# CY8C5888LTI_LP097 register map
File version: 0.1
CY8C58LP
Registers are 8-bit, read-write, no defined reset value unless marked. A register's access mark holds for its fields unless they carry their own. Offsets are from the block's base; lines under a group give offsets from that group; [hi:lo] are bit positions; {n}, {i} and the like mark numbered series; 'fields as' and 'values as' point back to an identical list; <NAME> marks a mode.

## Memory map
0x00000000 RC_Ch3_Timer
0x00000000 MPU6050_I2C
0x00000000 Flywheel_DC_Motor_PWM
0x00000000 Pendulum_DC_Motor_PWM
0x00000000 RC_Ch4_Timer
0x00000000 RC_Ch1_Timer
0x00000000 USBUART — USBFS
0x00000000 Drive_DC_Motor_PWM
0x00000000 RC_Ch2_Timer

## RC_Ch3_Timer
Base 0x00000000
0x40006404 RC_Ch3_Timer_COUNTER 24-bit — UDB.A0 - Current Down Counter Value
0x40006424 RC_Ch3_Timer_PERIOD 24-bit — UDB.D0 - Assigned Period
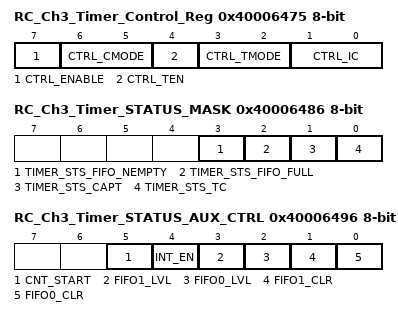
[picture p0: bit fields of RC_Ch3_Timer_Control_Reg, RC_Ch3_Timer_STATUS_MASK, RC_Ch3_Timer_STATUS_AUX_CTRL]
0x40006475 RC_Ch3_Timer_Control_Reg — UDB Control Register - Assigned Control Register Value
  [7] CTRL_ENABLE — Enable the Timer
  [6:5] CTRL_CMODE — Capture Mode
  [4] CTRL_TEN — Trigger Enable Bit
  [3:2] CTRL_TMODE — Trigger Mode
  [1:0] CTRL_IC — Interrupt Count
0x40006486 RC_Ch3_Timer_STATUS_MASK — UDB Status bits Interrupt Mask Enable Register
  [3] TIMER_STS_FIFO_NEMPTY ro — FIFO Empty status
  [2] TIMER_STS_FIFO_FULL ro — FIFO Full Status
  [1] TIMER_STS_CAPT ro — Enables the Interrupt on Capture
  [0] TIMER_STS_TC ro — Enables the Interrupt on TC
0x40006496 RC_Ch3_Timer_STATUS_AUX_CTRL — UDB Auxilliary Control Register
  [5] CNT_START — FIFO0 clear
    0=E_CNT_START0 (Disable counter); 1=E_CNT_START1 (Enable counter)
  [4] INT_EN
    0=E_INT_EN0 (Interrupt disabled); 1=E_INT_EN1 (Interrupt enabled)
  [3] FIFO1_LVL — FIFO level
    0=E_FIFO_LVL_0 (FIFO LVL: input mode: FIFO not full; output mode: FIFO not empty); 1=E_FIFO_LVL_1 (FIFO LVL: input mode: FIFO at least 1/2 empty; output mode: FIFO at least 1/2 full)
  [2] FIFO0_LVL — FIFO level
    values as FIFO1_LVL
  [1] FIFO1_CLR — FIFO1 clear
    0=E_FIFO_CLR_0 (Normal FIFO operation); 1=E_FIFO_CLR_1 (Clear FIFO state)
  [0] FIFO0_CLR — FIFO0 clear
    values as FIFO1_CLR

## Flywheel_DC_Motor_PWM
Base 0x00000000
0x40006427 Flywheel_DC_Motor_PWM__COMPARE1 — UDB.D0 - Assigned Compare1 Value
0x40006437 Flywheel_DC_Motor_PWM__COMPARE2 — UDB.D1 - Assigned Compare2 Value
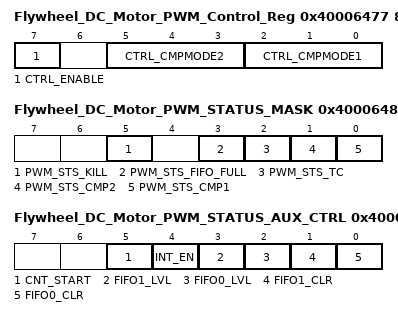
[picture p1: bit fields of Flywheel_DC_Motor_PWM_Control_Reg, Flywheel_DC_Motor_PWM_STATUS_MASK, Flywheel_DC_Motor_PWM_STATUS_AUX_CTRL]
0x40006477 Flywheel_DC_Motor_PWM_Control_Reg — UDB Control Register - Assigned Control Register Value
  [7] CTRL_ENABLE — Enable the PWM
  [5:3] CTRL_CMPMODE2 — Compare mode 2
  [2:0] CTRL_CMPMODE1 — Compare mode 1
0x40006487 Flywheel_DC_Motor_PWM_STATUS_MASK — UDB Status bits Interrupt Mask Enable Register
  [5] PWM_STS_KILL ro — Enables the Interrupt on Kill
  [3] PWM_STS_FIFO_FULL ro — FIFO Full Status Mask
  [2] PWM_STS_TC ro — Enables the Interrupt on Terminal Count
  [1] PWM_STS_CMP2 ro — Enables the Interrupt on Compare 2
  [0] PWM_STS_CMP1 ro — Enables the Interrupt on Compare 1
0x40006497 Flywheel_DC_Motor_PWM_STATUS_AUX_CTRL — UDB Auxilliary Control Register
  [5] CNT_START — FIFO0 clear
    0=E_CNT_START0 (Disable counter); 1=E_CNT_START1 (Enable counter)
  [4] INT_EN
    0=E_INT_EN0 (Interrupt disabled); 1=E_INT_EN1 (Interrupt enabled)
  [3] FIFO1_LVL — FIFO level
    0=E_FIFO_LVL_0 (FIFO LVL: input mode: FIFO not full; output mode: FIFO not empty); 1=E_FIFO_LVL_1 (FIFO LVL: input mode: FIFO at least 1/2 empty; output mode: FIFO at least 1/2 full)
  [2] FIFO0_LVL — FIFO level
    values as FIFO1_LVL
  [1] FIFO1_CLR — FIFO1 clear
    0=E_FIFO_CLR_0 (Normal FIFO operation); 1=E_FIFO_CLR_1 (Clear FIFO state)
  [0] FIFO0_CLR — FIFO0 clear
    values as FIFO1_CLR

## Pendulum_DC_Motor_PWM
Base 0x00000000
0x40006429 Pendulum_DC_Motor_PWM__COMPARE1 — UDB.D0 - Assigned Compare1 Value
0x40006439 Pendulum_DC_Motor_PWM__COMPARE2 — UDB.D1 - Assigned Compare2 Value
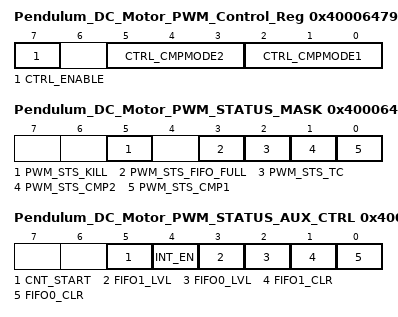
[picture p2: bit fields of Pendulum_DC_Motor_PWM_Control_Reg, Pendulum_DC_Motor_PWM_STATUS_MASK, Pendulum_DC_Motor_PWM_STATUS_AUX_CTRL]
0x40006479 Pendulum_DC_Motor_PWM_Control_Reg — UDB Control Register - Assigned Control Register Value
  [7] CTRL_ENABLE — Enable the PWM
  [5:3] CTRL_CMPMODE2 — Compare mode 2
  [2:0] CTRL_CMPMODE1 — Compare mode 1
0x40006489 Pendulum_DC_Motor_PWM_STATUS_MASK — UDB Status bits Interrupt Mask Enable Register
  [5] PWM_STS_KILL ro — Enables the Interrupt on Kill
  [3] PWM_STS_FIFO_FULL ro — FIFO Full Status Mask
  [2] PWM_STS_TC ro — Enables the Interrupt on Terminal Count
  [1] PWM_STS_CMP2 ro — Enables the Interrupt on Compare 2
  [0] PWM_STS_CMP1 ro — Enables the Interrupt on Compare 1
0x40006499 Pendulum_DC_Motor_PWM_STATUS_AUX_CTRL — UDB Auxilliary Control Register
  [5] CNT_START — FIFO0 clear
    0=E_CNT_START0 (Disable counter); 1=E_CNT_START1 (Enable counter)
  [4] INT_EN
    0=E_INT_EN0 (Interrupt disabled); 1=E_INT_EN1 (Interrupt enabled)
  [3] FIFO1_LVL — FIFO level
    0=E_FIFO_LVL_0 (FIFO LVL: input mode: FIFO not full; output mode: FIFO not empty); 1=E_FIFO_LVL_1 (FIFO LVL: input mode: FIFO at least 1/2 empty; output mode: FIFO at least 1/2 full)
  [2] FIFO0_LVL — FIFO level
    values as FIFO1_LVL
  [1] FIFO1_CLR — FIFO1 clear
    0=E_FIFO_CLR_0 (Normal FIFO operation); 1=E_FIFO_CLR_1 (Clear FIFO state)
  [0] FIFO0_CLR — FIFO0 clear
    values as FIFO1_CLR
